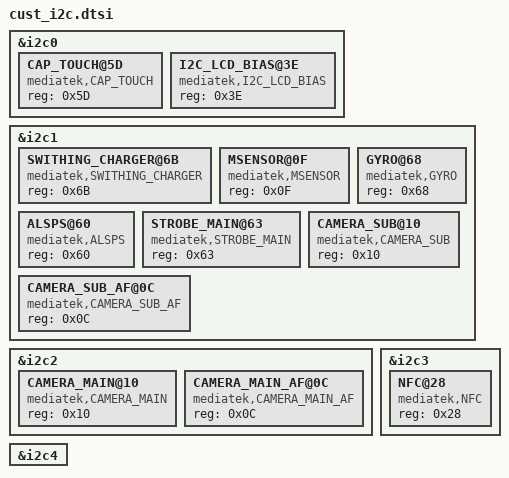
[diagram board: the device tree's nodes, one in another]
/*
 * Generated by MTK SP DrvGen Version 03.13.6 for MT6755. Copyright MediaTek Inc. (C) 2013.
 * Mon Aug 12 22:58:53 2019
 * Do Not Modify the File.
 */

/*************************
 * I2C DTSI File
*************************/

&i2c0 {
	CAP_TOUCH@5D {
		compatible = "mediatek,CAP_TOUCH";
		reg = <0x5D>;
	};

	I2C_LCD_BIAS@3E {
		compatible = "mediatek,I2C_LCD_BIAS";
		reg = <0x3E>;
	};

};

&i2c1 {
	SWITHING_CHARGER@6B {
		compatible = "mediatek,SWITHING_CHARGER";
		reg = <0x6B>;
	};

	MSENSOR@0F {
		compatible = "mediatek,MSENSOR";
		reg = <0x0F>;
	};

	GYRO@68 {
		compatible = "mediatek,GYRO";
		reg = <0x68>;
	};

	ALSPS@60 {
		compatible = "mediatek,ALSPS";
		reg = <0x60>;
	};

	STROBE_MAIN@63 {
		compatible = "mediatek,STROBE_MAIN";
		reg = <0x63>;
	};

	CAMERA_SUB@10 {
		compatible = "mediatek,CAMERA_SUB";
		reg = <0x10>;
	};

	CAMERA_SUB_AF@0C {
		compatible = "mediatek,CAMERA_SUB_AF";
		reg = <0x0C>;
	};

};

&i2c2 {
	CAMERA_MAIN@10 {
		compatible = "mediatek,CAMERA_MAIN";
		reg = <0x10>;
	};

	CAMERA_MAIN_AF@0C {
		compatible = "mediatek,CAMERA_MAIN_AF";
		reg = <0x0C>;
	};

};

&i2c3 {
	NFC@28 {
		compatible = "mediatek,NFC";
		reg = <0x28>;
	};

};

&i2c4 {
};

